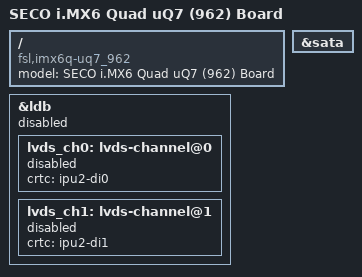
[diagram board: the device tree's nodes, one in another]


/dts-v1/;

#include "imx6q.dtsi"
#include "imx6qdl-seco_uQ7_962.dtsi"
#include "imx6qdl-seco_lvds_display.dtsi"

/ {
	model = "SECO i.MX6 Quad uQ7 (962) Board";
	compatible = "fsl,imx6q-uq7_962", "fsl,imx6q";
};

&ldb {
	status = "disabled";

	lvds_ch0: lvds-channel@0 {
		status = "disabled";
		crtc   = "ipu2-di0";
	};

	lvds_ch1: lvds-channel@1 {
		status = "disabled";
		crtc   = "ipu2-di1";
	};	
};


&sata {
	status = "okay";
};
